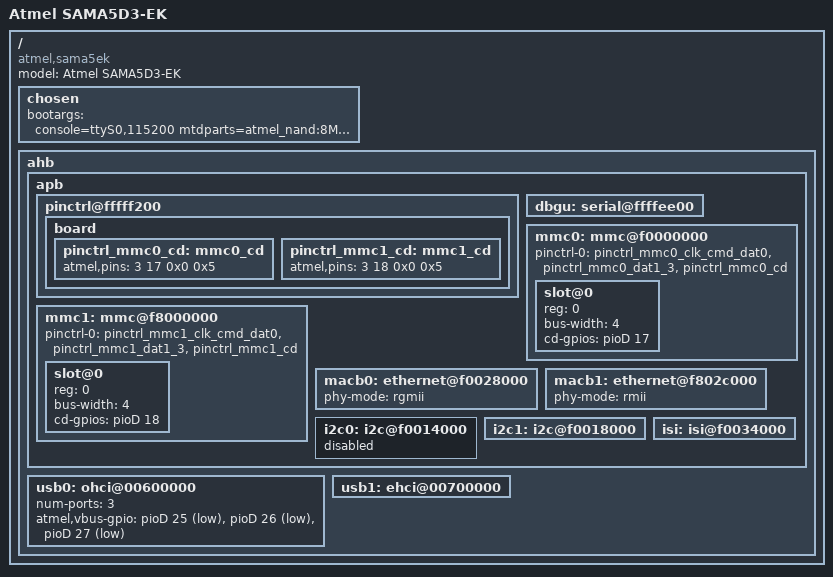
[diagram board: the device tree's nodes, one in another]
/*
 * sama5d35ek.dts - Device Tree file for SAMA5-EK board
 *
 *  Copyright (C) 2012 Atmel,
 *                2012 Ludovic Desroches <ludovic.desroches@atmel.com>
 *
 * Licensed under GPLv2 or later.
 */
/dts-v1/;
/include/ "sama5d3.dtsi"
/include/ "sama5d3cm.dtsi"

/ {
	model = "Atmel SAMA5D3-EK";
	compatible = "atmel,sama5ek", "atmel,sama5d3", "atmel,sama5";

	chosen {
		bootargs = "console=ttyS0,115200 mtdparts=atmel_nand:8M(bootstrap/uboot/kernel)ro,-(rootfs) rw rootfstype=ubifs ubi.mtd=1 root=ubi0:rootfs";
	};

	ahb {
		apb {
			pinctrl@fffff200 {
				board {
					pinctrl_mmc0_cd: mmc0_cd {
						atmel,pins =
							<3 17 0x0 0x5>; /* PD17 periph A with pullup deglitch */
					};

					pinctrl_mmc1_cd: mmc1_cd {
						atmel,pins =
							<3 18 0x0 0x5>; /* PD18 periph A with pullup deglitch */
					};
				};
			};

			dbgu: serial@ffffee00 {
				status = "okay";
			};

			mmc0: mmc@f0000000 {
				status = "okay";
				pinctrl-0 = <&pinctrl_mmc0_clk_cmd_dat0 &pinctrl_mmc0_dat1_3 &pinctrl_mmc0_cd>;
				slot@0 {
					reg = <0>;
					bus-width = <4>;
					cd-gpios = <&pioD 17 0>;
				};
			};

			mmc1: mmc@f8000000 {
				status = "okay";
				pinctrl-0 = <&pinctrl_mmc1_clk_cmd_dat0 &pinctrl_mmc1_dat1_3 &pinctrl_mmc1_cd>;
				slot@0 {
					reg = <0>;
					bus-width = <4>;
					cd-gpios = <&pioD 18 0>;
				};
			};

			macb0: ethernet@f0028000 {
				phy-mode = "rgmii";
				status = "okay";
			};

			macb1: ethernet@f802c000 {
				phy-mode = "rmii";
				status = "okay";
			};

			/*
			 * i2c0 conflicts with ISI:
			 * disable it to allow the use of ISI
			 */
			i2c0: i2c@f0014000 {
				status = "disabled";
			};

			i2c1: i2c@f0018000 {
				status = "okay";
			};

			isi: isi@f0034000 {
				status = "okay";
			};
		};

		usb0: ohci@00600000 {
			status = "okay";
			num-ports = <3>;
			atmel,vbus-gpio = <&pioD 25 1
					   &pioD 26 1
					   &pioD 27 1
					  >;
		};

		usb1: ehci@00700000 {
			status = "okay";
		};

	};
};
